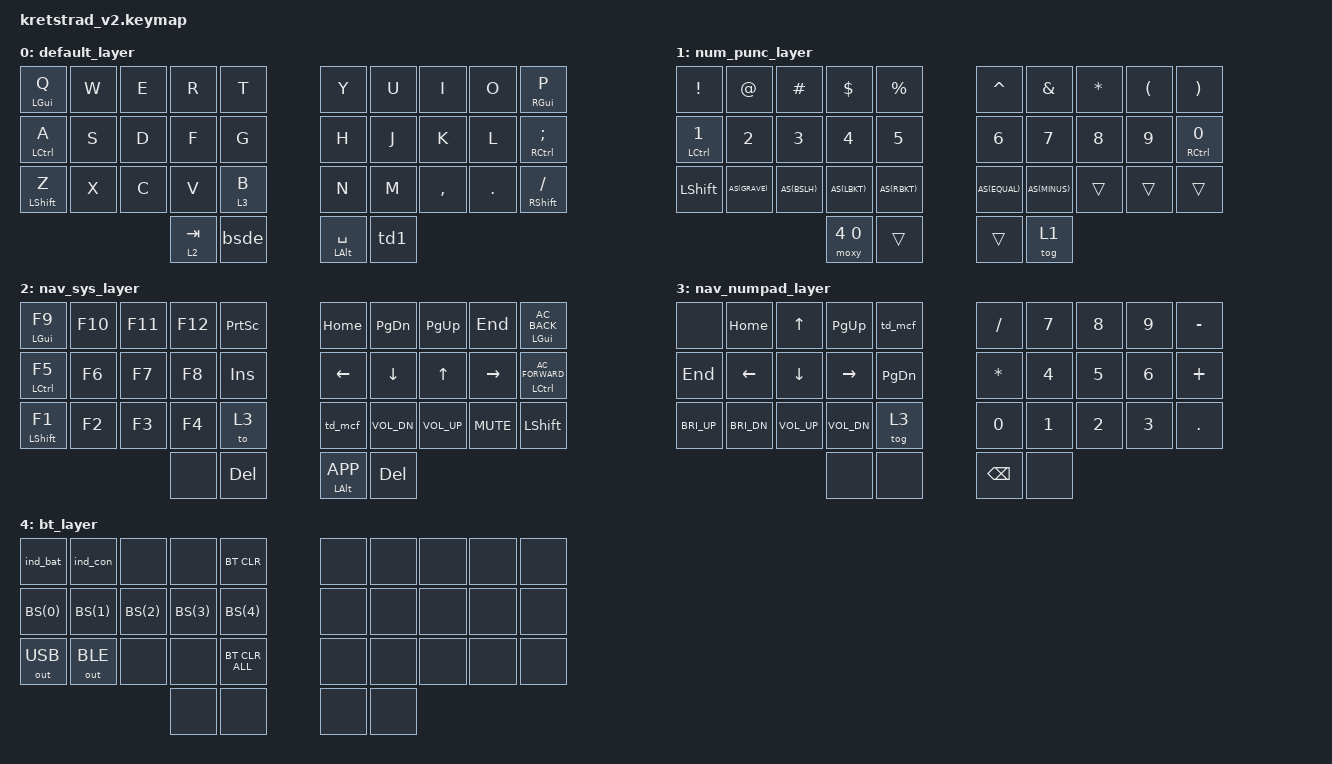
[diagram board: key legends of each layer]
/*
 * Copyright (c) 2020 The ZMK Contributors
 *
 * SPDX-License-Identifier: MIT
 */

#include <behaviors.dtsi>
#include <dt-bindings/zmk/keys.h>
#include <dt-bindings/zmk/bt.h>
#include <dt-bindings/zmk/outputs.h>
#include <behaviors/rgbled_widget.dtsi>  // show battery or connectivity status on demand

#define AS(keycode) &as keycode keycode     // Autoshift Macro
#define BS(keycode) &bt BT_SEL keycode     // Bluetooth profile selection macro

&sl {
    release-after-ms = <500>;
    /delete-property/ quick-release;
};

&lt {
    quick-tap-ms = <250>;
};

/ {

    macros {
        moxy: mo_to_x_back_to_y {
            compatible = "zmk,behavior-macro-two-param";
            #binding-cells = <2>;
            wait-ms = <0>;
            tap-ms = <0>;
            bindings
                = <&macro_param_1to1>
                , <&macro_press &mo MACRO_PLACEHOLDER>
                , <&macro_pause_for_release>
                , <&macro_param_1to1>
                , <&macro_release &mo MACRO_PLACEHOLDER>
                , <&macro_param_2to1>
                , <&macro_tap &to MACRO_PLACEHOLDER>
                ;
        };

        as_s: autoshift_single {
            compatible = "zmk,behavior-macro-one-param";
            #binding-cells = <1>;
            wait-ms = <0>;
            tap-ms = <0>;
            bindings
                = <&macro_press &kp LSHFT>
                , <&macro_param_1to1>
                , <&macro_tap &kp MACRO_PLACEHOLDER>
                , <&macro_release &kp LSHFT>
                ;
        };

    };

    behaviors {
        ht: hold_tap_standard {
            compatible = "zmk,behavior-hold-tap";
            #binding-cells = <2>;
            tapping-term-ms = <175>;
            quick-tap-ms = <225>;
            flavor = "tap-preferred";
            bindings = <&kp>, <&kp>;
        };

        hb: hold_tap_balanced {
            compatible = "zmk,behavior-hold-tap";
            #binding-cells = <2>;
            tapping-term-ms = <175>;
            quick-tap-ms = <225>;
            flavor = "balanced";
            bindings = <&kp>, <&kp>;
        };

        hh: hold_tap_hold_preferred {
            compatible = "zmk,behavior-hold-tap";
            #binding-cells = <2>;
            tapping-term-ms = <150>;
            quick-tap-ms = <225>;
            // hold-while-undecided;
            flavor = "hold-preferred";
            bindings = <&kp>, <&kp>;
        };

        lh: layer_tap_hold_pref {
            compatible = "zmk,behavior-hold-tap";
            #binding-cells = <2>;
            tapping-term-ms = <125>;
            flavor = "hold-preferred";
            bindings = <&mo>, <&kp>;
        };

        as: auto_shift_key  {
            compatible = "zmk,behavior-hold-tap";
            #binding-cells = <2>;
            tapping-term-ms = <225>;
            flavor = "tap-preferred";
            bindings = <&as_s>, <&kp>;
        };

        bsde: backspace_delete {
            compatible = "zmk,behavior-mod-morph";
            #binding-cells = <0>;
            bindings = <&hb LALT BSPC>, <&kp DELETE>;
            mods = <(MOD_LSFT|MOD_RSFT)>;
            /* keep-mods = <(MOD_RSFT)>; */
        };

        td1: tap_dance_layer_1 {
            compatible = "zmk,behavior-tap-dance";
            #binding-cells = <0>;
            tapping-term-ms = <250>;
            bindings = <&sl 1>, <&to 1>;
        };

        td_mcf: tap_dance_media_control_full {
            compatible = "zmk,behavior-tap-dance";
            #binding-cells = <0>;
            tapping-term-ms = <250>;
            bindings = <&kp C_PP>, <&kp C_NEXT>, <&kp C_PREV>;
        };

    };

    keymap {
        compatible = "zmk,keymap";

        default_layer {
            bindings = <
                &ht LGUI Q   &kp W  &kp E  &kp R      &kp T        &kp Y           &kp U  &kp I      &kp O    &ht RGUI P
                &ht LCTRL A  &kp S  &kp D  &kp F      &kp G        &kp H           &kp J  &kp K      &kp L    &ht RCTRL SEMI
                &hh LSHFT Z  &kp X  &kp C  &kp V      &lt 3 B      &kp N           &kp M  &kp COMMA  &kp DOT  &hh RSHFT FSLH
                                           &lh 2 TAB  &bsde        &hb LALT SPACE  &td1
                >;
        };

        // Numbers and punctuations each on separate row
        num_punc_layer {
            bindings = <
                &kp EXCL      &kp AT     &kp HASH  &kp DLLR   &kp PRCNT      &kp CARET  &kp AMPS   &kp STAR  &kp LPAR  &kp RPAR
                &ht LCTRL N1  &kp N2     &kp N3    &kp N4     &kp N5         &kp N6     &kp N7     &kp N8    &kp N9    &ht RCTRL N0
                &kp LSHFT     AS(GRAVE)  AS(BSLH)  AS(LBKT)   AS(RBKT)       AS(EQUAL)  AS(MINUS)  &trans    &trans    &trans
                                                   &moxy 4 0  &trans         &trans     &tog 1
                >;
        };

        nav_sys_layer {
            bindings = <
                &ht LGUI F9   &kp F10  &kp F11  &kp F12  &kp PSCRN      &kp HOME        &kp PG_DN     &kp PG_UP     &kp END     &ht LGUI C_AC_BACK
                &ht LCTRL F5  &kp F6   &kp F7   &kp F8   &kp INS        &kp LEFT        &kp DOWN      &kp UP        &kp RIGHT   &ht LCTRL C_AC_FORWARD
                &hh LSHFT F1  &kp F2   &kp F3   &kp F4   &to 3          &td_mcf         &kp C_VOL_DN  &kp C_VOL_UP  &kp C_MUTE  &kp LSHFT
                                                &none    &kp DELETE     &hb LALT K_APP  &kp DELETE
                >;
        };

        nav_numpad_layer {
            bindings = <
                &none         &kp HOME     &kp UP        &kp PG_UP     &td_mcf        &kp FSLH  &kp N7  &kp N8  &kp N9  &kp MINUS
                &kp END       &kp LEFT     &kp DOWN      &kp RIGHT     &kp PG_DN      &kp STAR  &kp N4  &kp N5  &kp N6  &kp PLUS
                &kp C_BRI_UP  &kp C_BRI_DN &kp C_VOL_UP  &kp C_VOL_DN  &tog 3         &kp N0    &kp N1  &kp N2  &kp N3  &kp DOT
                                                         &none         &none          &kp BSPC  &none
                >;
        };

        bt_layer {
            bindings = <
                &ind_bat      &ind_con      &none  &none  &bt BT_CLR        &none  &none  &none  &none  &none 
                BS(0)         BS(1)         BS(2)  BS(3)  BS(4)             &none  &none  &none  &none  &none  
                &out OUT_USB  &out OUT_BLE  &none  &none  &bt BT_CLR_ALL    &none  &none  &none  &none  &none
                                                   &none  &none             &none  &none
                >;
        };

    };

    combos {
        compatible = "zmk,combos";

        combo_equal {
            timeout-ms = <50>;
            key-positions = <0 1>;
            layers = <0 1>;
            bindings = <AS(EQUAL)>;
        };

        combo_plus {
            timeout-ms = <50>;
            slow-release;
            key-positions = <1 12>;
            layers = <0 1>;
            bindings = <&kp PLUS>;
        };

        combo_under_score {
            timeout-ms = <50>;
            slow-release;
            key-positions = <8 17>;
            layers = <0 1>;
            bindings = <&kp UNDER>;
        };

        combo_minus {
            timeout-ms = <50>;
            key-positions = <8 9>;
            layers = <0 1>;
            bindings = <AS(MINUS)>;
        };

        combo_left_bracket {
            timeout-ms = <50>;
            slow-release;
            key-positions = <2 13>;
            layers = <0>;
            bindings = <AS(LBKT)>;
        };

        combo_left_brace {
            timeout-ms = <50>;
            slow-release;
            key-positions = <3 14>;
            layers = <0>;
            bindings = <&kp LBRC>;
        };

        combo_right_brace {
            timeout-ms = <50>;
            slow-release;
            key-positions = <6 15>;
            layers = <0>;
            bindings = <&kp RBRC>;
        };

        combo_right_bracket {
            timeout-ms = <50>;
            slow-release;
            key-positions = <7 16>;
            layers = <0>;
            bindings = <AS(RBKT)>;
        };

        combo_tilde {
            timeout-ms = <50>;
            key-positions = <20 21>;
            layers = <0>;
            bindings = <&kp TILDE>;
        };

        combo_grave {
            timeout-ms = <50>;
            key-positions = <21 22>;
            layers = <0>;
            bindings = <AS(GRAVE)>;
        };

        combo_back_slash {
            timeout-ms = <50>;
            key-positions = <27 28>;
            layers = <0>;
            bindings = <AS(BSLH)>;
        };

        combo_pipe {
            timeout-ms = <50>;
            key-positions = <28 29>;
            layers = <0>;
            bindings = <&kp PIPE>;
        };

        combo_single_quote {
            timeout-ms = <50>;
            key-positions = <7 8>;
            layers = <0>;
            bindings = <AS(SQT)>;
        };

        combo_double_quote {
            timeout-ms = <50>;
            key-positions = <18 19>;
            layers = <0>;
            bindings = <&kp DQT>;
        };

        combo_enter {
            timeout-ms = <50>;
            key-positions = <17 18>;
            layers = <0 1 3>;
            bindings = <&kp ENTER>;
        };

        combo_caps {
            timeout-ms = <50>;
            slow-release;
            key-positions = <11 12>;
            layers = <0>;
            bindings = <&kp CAPS>;
        };

        combo_esc {
            timeout-ms = <50>;
            key-positions = <1 2>;
            layers = <0 1 2 3>;
            bindings = <&kp ESC>;
        };

        combo_esc_clear {
            timeout-ms = <50>;
            key-positions = <7 8>;
            layers = <3>;
            bindings = <&kp ESC>;
        };

        combo_del {
            timeout-ms = <50>;
            key-positions = <30 31>;
            layers = <0 1 2 3>;
            bindings = <&kp DELETE>;
        };

        combo_mcf {
            timeout-ms = <50>;
            key-positions = <32 33>;
            layers = <0>;
            bindings = <&td_mcf>;
        };

        combo_L2 {
            timeout-ms = <50>;
            key-positions = <16 17 18>;
            layers = <0 2>;
            bindings = <&tog 2>;
        };

        combo_L3 {
            timeout-ms = <50>;
            key-positions = <26 27 28>;
            layers = <0 3>;
            bindings = <&tog 3>;
        };

        combo_L4 {
            timeout-ms = <50>;
            key-positions = <26 27 28 29>;
            layers = <0 1 2 3>;
            bindings = <&mo 4>;
        };

    };

};

